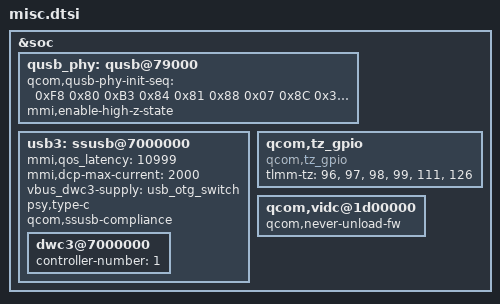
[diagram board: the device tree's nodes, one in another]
/* Copyright (c) 2018, Motorola Mobility Inc. All rights reserved.
 *
 * This program is free software; you can redistribute it and/or modify
 * it under the terms of the GNU General Public License version 2 and
 * only version 2 as published by the Free Software Foundation.
 *
 * This program is distributed in the hope that it will be useful,
 * but WITHOUT ANY WARRANTY; without even the implied warranty of
 * MERCHANTABILITY or FITNESS FOR A PARTICULAR PURPOSE.  See the
 * GNU General Public License for more details.
 */

&soc {
	qusb_phy: qusb@79000 {
		qcom,qusb-phy-init-seq = <0xF8 0x80
					0xB3 0x84
					0x81 0x88
					0x07 0x8C
					0x30 0x08
					0x79 0x0C
					0x21 0x10
					0x14 0x9C
					0x9F 0x1C
					0x00 0x18>;
		/*Make sure QUSB PHY is into proper state to
		  avoid interfering USB charger detection*/
		mmi,enable-high-z-state;
	};

	usb3: ssusb@7000000 {
		mmi,qos_latency = <10999>;
		/delete-property/ pinctrl-names;
		/delete-property/ pinctrl-0;
		/delete-property/ qcom,otg-fault-gpio;
		mmi,dcp-max-current = <2000>;
		vbus_dwc3-supply = <&usb_otg_switch>;
		psy,type-c;
		qcom,ssusb-compliance;
		dwc3@7000000 {
			controller-number = /bits/ 8 <1>;
		};
	};

	qcom,tz_gpio {
		compatible = "qcom,tz_gpio";
		tlmm-tz = <96>,
			<97>,
			<98>,
			<99>,
			<111>,
			<126>;
	};

	qcom,vidc@1d00000 {
		qcom,never-unload-fw;
	};
};
